# STM32F100xx register map
File version: 1.1
Registers are 32-bit, read-write, reset 0x0 unless marked. A register's access mark holds for its fields unless they carry their own. Offsets are from the block's base; [hi:lo] are bit positions; {n}, {i} and the like mark numbered series.

## UART5 — Universal asynchronous receiver transmitter
Base 0x40005000
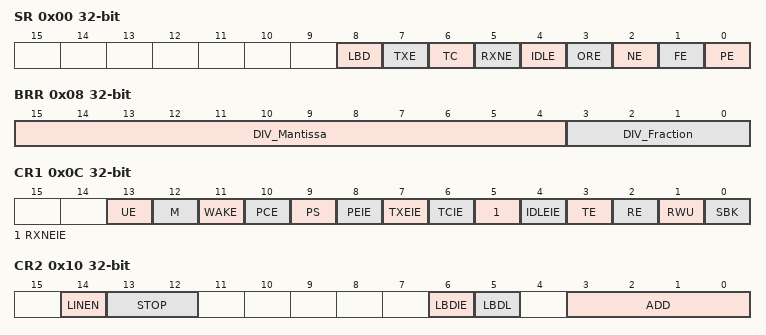
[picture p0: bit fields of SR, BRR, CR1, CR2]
0x00 SR access per field — Status register
  [8] LBD rw, [7] TXE ro, [6] TC rw, [5] RXNE rw, [4] IDLE ro, [3] ORE ro, [2] NE ro, [1] FE ro, [0] PE ro
0x04 DR — Data register
  [8:0] DR
0x08 BRR — Baud rate register
  [15:4] DIV_Mantissa, [3:0] DIV_Fraction
0x0C CR1 — Control register 1
  [13] UE, [12] M, [11] WAKE, [10] PCE, [9] PS, [8] PEIE, [7] TXEIE, [6] TCIE, [5] RXNEIE, [4] IDLEIE, [3] TE, [2] RE, [1] RWU, [0] SBK
0x10 CR2 — Control register 2
  [14] LINEN, [13:12] STOP, [6] LBDIE, [5] LBDL, [3:0] ADD
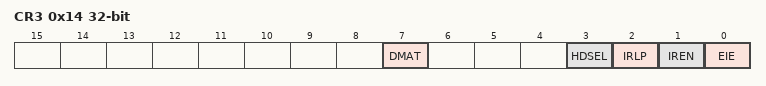
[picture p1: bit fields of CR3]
0x14 CR3 — Control register 3
  [7] DMAT — DMA enable transmitter
  [3] HDSEL — Half-duplex selection
  [2] IRLP — IrDA low-power
  [1] IREN — IrDA mode enable
  [0] EIE — Error interrupt enable

## CRC — CRC calculation unit
Base 0x40023000
0x00 DR reset 0xFFFFFFFF — Data register
  [31:0] DR — Data Register
0x04 IDR — Independent Data register
  [7:0] IDR
0x08 CR wo — Control register
  [0] RESET — Reset bit

## FLASH
Base 0x40022000
0x00 ACR — Flash access control register
  [3] HLFCYA — Flash half cycle access enable
0x04 KEYR wo — Flash key register
  [31:0] KEY — FPEC key
0x08 OPTKEYR wo — Flash option key register
  [31:0] OPTKEY — Option byte key
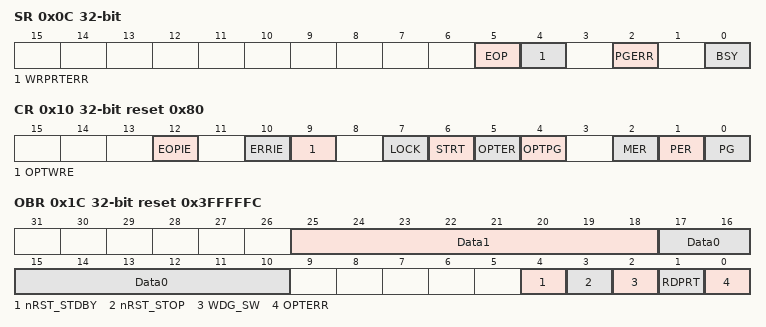
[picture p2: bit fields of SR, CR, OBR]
0x0C SR access per field — Status register
  [5] EOP rw — End of operation
  [4] WRPRTERR rw — Write protection error
  [2] PGERR rw — Programming error
  [0] BSY ro — Busy
0x10 CR reset 0x80 — Control register
  [12] EOPIE — End of operation interrupt enable
  [10] ERRIE — Error interrupt enable
  [9] OPTWRE — Option bytes write enable
  [7] LOCK
  [6] STRT — Start
  [5] OPTER — Option byte erase
  [4] OPTPG — Option byte programming
  [2] MER — Mass Erase
  [1] PER — Page Erase
  [0] PG — Programming
0x14 AR wo — Flash address register
  [31:0] FAR — Flash Address
0x1C OBR ro reset 0x3FFFFFC — Option byte register
  [25:18] Data1
  [17:10] Data0
  [4] nRST_STDBY
  [3] nRST_STOP
  [2] WDG_SW
  [1] RDPRT — Read protection
  [0] OPTERR — Option byte error
0x20 WRPR ro reset 0xFFFFFFFF — Write protection register
  [31:0] WRP — Write protect

## TIM16 — General-purpose-timers
Base 0x40014400
Same registers: TIM17 0x40014800
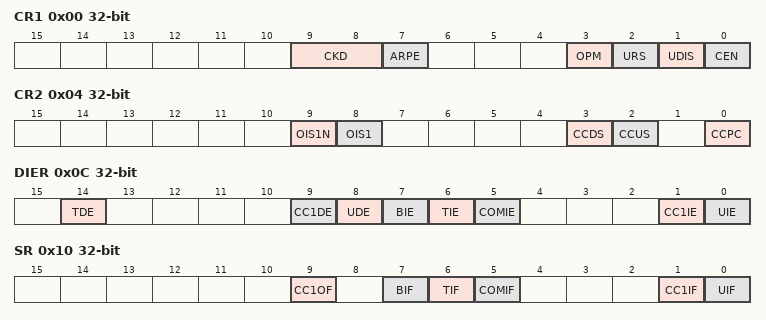
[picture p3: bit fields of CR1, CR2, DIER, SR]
0x00 CR1 — control register 1
  [9:8] CKD — Clock division
  [7] ARPE — Auto-reload preload enable
  [3] OPM — One-pulse mode
  [2] URS — Update request source
  [1] UDIS — Update disable
  [0] CEN — Counter enable
0x04 CR2 — control register 2
  [9] OIS1N — Output Idle state 1
  [8] OIS1 — Output Idle state 1
  [3] CCDS — Capture/compare DMA selection
  [2] CCUS — Capture/compare control update selection
  [0] CCPC — Capture/compare preloaded control
0x0C DIER — DMA/Interrupt enable register
  [14] TDE — Trigger DMA request enable
  [9] CC1DE — Capture/Compare 1 DMA request enable
  [8] UDE — Update DMA request enable
  [7] BIE — Break interrupt enable
  [6] TIE — Trigger interrupt enable
  [5] COMIE — COM interrupt enable
  [1] CC1IE — Capture/Compare 1 interrupt enable
  [0] UIE — Update interrupt enable
0x10 SR — status register
  [9] CC1OF — Capture/Compare 1 overcapture flag
  [7] BIF — Break interrupt flag
  [6] TIF — Trigger interrupt flag
  [5] COMIF — COM interrupt flag
  [1] CC1IF — Capture/compare 1 interrupt flag
  [0] UIF — Update interrupt flag
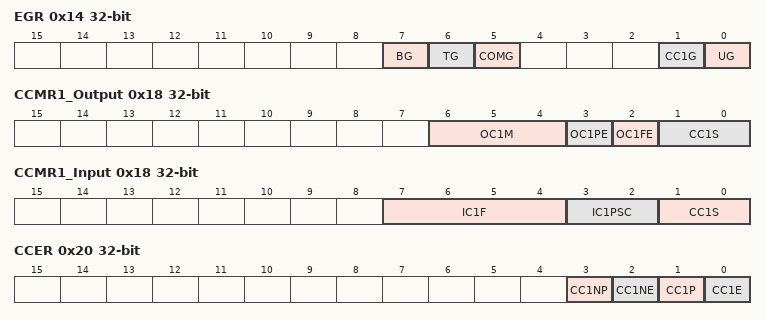
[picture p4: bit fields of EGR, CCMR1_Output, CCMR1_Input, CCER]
0x14 EGR wo — event generation register
  [7] BG — Break generation
  [6] TG — Trigger generation
  [5] COMG — Capture/Compare control update generation
  [1] CC1G — Capture/compare 1 generation
  [0] UG — Update generation
0x18 CCMR1_Output — capture/compare mode register (output mode)
  [6:4] OC1M — Output Compare 1 mode
  [3] OC1PE — Output Compare 1 preload enable
  [2] OC1FE — Output Compare 1 fast enable
  [1:0] CC1S — Capture/Compare 1 selection
0x18 CCMR1_Input (alternate view of CCMR1_Output) — capture/compare mode register 1 (input mode)
  [7:4] IC1F — Input capture 1 filter
  [3:2] IC1PSC — Input capture 1 prescaler
  [1:0] CC1S — Capture/Compare 1 selection
0x20 CCER — capture/compare enable register
  [3] CC1NP — Capture/Compare 1 output Polarity
  [2] CC1NE — Capture/Compare 1 complementary output enable
  [1] CC1P — Capture/Compare 1 output Polarity
  [0] CC1E — Capture/Compare 1 output enable
0x24 CNT — counter
  [15:0] CNT — counter value
0x28 PSC — prescaler
  [15:0] PSC — Prescaler value
0x2C ARR — auto-reload register
  [15:0] ARR — Auto-reload value
0x30 RCR — repetition counter register
  [7:0] REP — Repetition counter value
0x34 CCR1 — capture/compare register 1
  [15:0] CCR1 — Capture/Compare 1 value
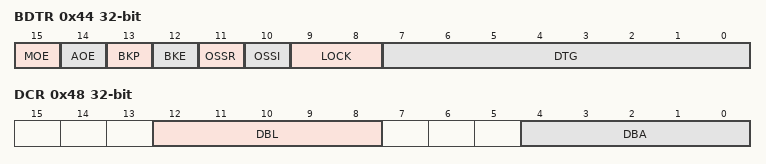
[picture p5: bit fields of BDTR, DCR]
0x44 BDTR — break and dead-time register
  [15] MOE — Main output enable
  [14] AOE — Automatic output enable
  [13] BKP — Break polarity
  [12] BKE — Break enable
  [11] OSSR — Off-state selection for Run mode
  [10] OSSI — Off-state selection for Idle mode
  [9:8] LOCK — Lock configuration
  [7:0] DTG — Dead-time generator setup
0x48 DCR — DMA control register
  [12:8] DBL — DMA burst length
  [4:0] DBA — DMA base address
0x4C DMAR — DMA address for full transfer
  [15:0] DMAB — DMA register for burst accesses

## CEC — HDMI-CEC controller
Base 0x40007800
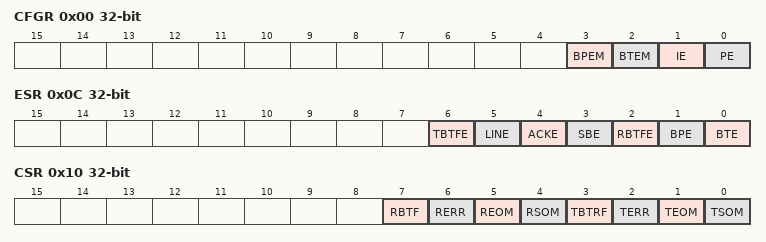
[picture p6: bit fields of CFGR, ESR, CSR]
0x00 CFGR — configuration register
  [3] BPEM — Bit period error mode
  [2] BTEM — Bit timing error mode
  [1] IE — Interrupt enable
  [0] PE — Peripheral enable
0x04 OAR — CEC own address register
  [3:0] OA — Own address
0x08 PRES — Rx Data Register
  [13:0] PRESC — CEC Rx Data Register
0x0C ESR ro — CEC error status register
  [6] TBTFE — Tx block transfer finished error
  [5] LINE — Line error
  [4] ACKE — Block acknowledge error
  [3] SBE — Start bit error
  [2] RBTFE — Rx block transfer finished error
  [1] BPE — Bit period error
  [0] BTE — Bit timing error
0x10 CSR — CEC control and status register
  [7] RBTF — Rx byte/block transfer finished
  [6] RERR — Rx error
  [5] REOM — Rx end of message
  [4] RSOM — Rx start of message
  [3] TBTRF — Tx byte transfer request or block transfer finished
  [2] TERR — Tx error
  [1] TEOM — Tx end of message
  [0] TSOM — Tx start of message
0x14 TXD — CEC Tx data register
  [7:0] TXD — Tx Data register
0x18 RXD ro — CEC Rx data register
  [7:0] RXD — Rx data

## NVIC — Nested Vectored Interrupt Controller
Base 0xE000E000
0x04 ICTR ro — Interrupt Controller Type Register
  [3:0] INTLINESNUM — Total number of interrupt lines in groups
0x100 ISER0 — Interrupt Set-Enable Register
  [31:0] SETENA
0x104 ISER1 — Interrupt Set-Enable Register
  [31:0] SETENA
0x180 ICER0 — Interrupt Clear-Enable Register
  [31:0] CLRENA
0x184 ICER1 — Interrupt Clear-Enable Register
  [31:0] CLRENA
0x200 ISPR0 — Interrupt Set-Pending Register
  [31:0] SETPEND
0x204 ISPR1 — Interrupt Set-Pending Register
  [31:0] SETPEND
0x280 ICPR0 — Interrupt Clear-Pending Register
  [31:0] CLRPEND
0x284 ICPR1 — Interrupt Clear-Pending Register
  [31:0] CLRPEND
0x300 IABR0 ro — Interrupt Active Bit Register
  [31:0] ACTIVE
0x304 IABR1 ro — Interrupt Active Bit Register
  [31:0] ACTIVE
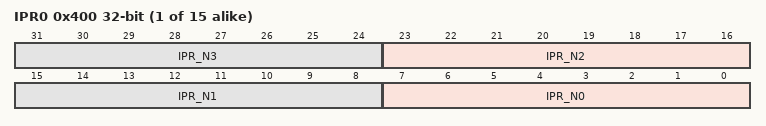
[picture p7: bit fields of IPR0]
{0x400+4i} IPR{i} (i=0..14) — Interrupt Priority Register
  [8n+7:8n] IPR_N{n} (n=0..3)
0xF00 STIR wo — Software Triggered Interrupt Register
  [8:0] INTID — interrupt to be triggered
